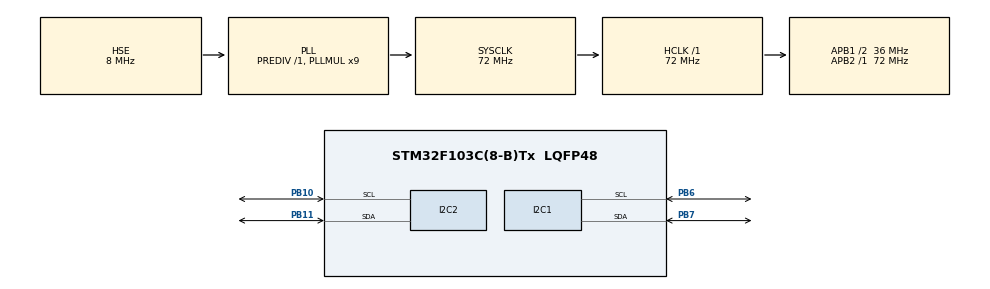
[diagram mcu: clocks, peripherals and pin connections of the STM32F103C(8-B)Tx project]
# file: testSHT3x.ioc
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Mcu.Family=STM32F1
Mcu.Name=STM32F103C(8-B)Tx
Mcu.Package=LQFP48
NVIC.PriorityGroup=NVIC_PRIORITYGROUP_4
PA13.Mode=Serial_Wire
PA13.Signal=SYS_JTMS-SWDIO
PA14.Mode=Serial_Wire
PA14.Signal=SYS_JTCK-SWCLK
PB10.Mode=I2C
PB10.Signal=I2C2_SCL
PB11.Mode=I2C
PB11.Signal=I2C2_SDA
PB6.Mode=I2C
PB6.Signal=I2C1_SCL
PB7.Mode=I2C
PB7.Signal=I2C1_SDA
PD0-OSC_IN.Mode=HSE-External-Oscillator
PD0-OSC_IN.Signal=RCC_OSC_IN
PD1-OSC_OUT.Mode=HSE-External-Oscillator
PD1-OSC_OUT.Signal=RCC_OSC_OUT
ProjectManager.HeapSize=0x200
ProjectManager.StackSize=0x400
ProjectManager.TargetToolchain=MDK-ARM V5.32
RCC.AHBFreq_Value=72000000
RCC.APB1CLKDivider=RCC_HCLK_DIV2
RCC.APB1Freq_Value=36000000
RCC.APB1TimFreq_Value=72000000
RCC.APB2Freq_Value=72000000
RCC.APB2TimFreq_Value=72000000
RCC.HCLKFreq_Value=72000000
RCC.PLLMUL=RCC_PLL_MUL9
RCC.PLLSourceVirtual=RCC_PLLSOURCE_HSE
RCC.SYSCLKFreq_VALUE=72000000
RCC.SYSCLKSource=RCC_SYSCLKSOURCE_PLLCLK
RCC.USBFreq_Value=72000000
board=custom

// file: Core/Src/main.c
/* USER CODE BEGIN Header */
/**
  ******************************************************************************
  * @file           : main.c
  * @brief          : Main program body
  ******************************************************************************
  * @attention
  *
  * Copyright (c) 2024 STMicroelectronics.
  * All rights reserved.
  *
  * This software is licensed under terms that can be found in the LICENSE file
  * in the root directory of this software component.
  * If no LICENSE file comes with this software, it is provided AS-IS.
  *
  ******************************************************************************
  */
/* USER CODE END Header */
#include "main.h"

/* USER CODE BEGIN PD */
uint8_t buffer_r[6] = {0,0,0,0,0,0};
uint8_t command_buffer[2] = {0x2C, 0x06};
float temp;
float temperature, humidity;
/* USER CODE END PD */

/* USER CODE BEGIN PM */
uint16_t uint8_to_uint16(uint8_t msb, uint8_t lsb)
{
	return (uint16_t)((uint16_t)msb << 8u) | lsb;
}
/* USER CODE END PM */

I2C_HandleTypeDef hi2c1;
I2C_HandleTypeDef hi2c2;

void SystemClock_Config(void);
static void MX_GPIO_Init(void);
static void MX_I2C2_Init(void);
static void MX_I2C1_Init(void);

int main(void)
{

  /* MCU Configuration--------------------------------------------------------*/

  /* Reset of all peripherals, Initializes the Flash interface and the Systick. */
  HAL_Init();

  /* Configure the system clock */
  SystemClock_Config();

  /* Initialize all configured peripherals */
  MX_GPIO_Init();
  MX_I2C2_Init();
  MX_I2C1_Init();
  /* USER CODE BEGIN 2 */
//	uint8_t i = 0, ret;
//	for(i=1; i<128; i++)
//    {
//        ret = HAL_I2C_IsDeviceReady(&hi2c2, 0x44 << 1u, 3, 5);
//        if (ret != HAL_OK) /* No ACK Received At That Address */
//        {
////            HAL_UART_Transmit(&huart1, Space, sizeof(Space), 10000);
//        }
//        else if(ret == HAL_OK)
//        {
//            sprintf(Buffer, "0x%X", i);
////            HAL_UART_Transmit(&huart1, Buffer, sizeof(Buffer), 10000);
//        }
//   }
  /* USER CODE END 2 */

  /* Infinite loop */
  while (1)
  {

    /* USER CODE BEGIN 3 */
		HAL_I2C_Master_Transmit(&hi2c2, 0x44 << 1u, command_buffer, sizeof(command_buffer), 200);
//		HAL_I2C_Master_Transmit(&hi2c1, 0x44 << 1u, command_buffer, sizeof(command_buffer), 200);
		//HAL_I2C_Master_Transmit(&hi2c1,0x44<<1u, buffer, sizeof(buffer),200);
		HAL_I2C_Master_Receive(&hi2c2 , 0x44<<1u, buffer_r, sizeof(buffer_r), 200);
		uint16_t temperature_raw = uint8_to_uint16(buffer_r[0], buffer_r[1]);
		uint16_t humidity_raw = uint8_to_uint16(buffer_r[3], buffer_r[4]);

		temperature = -45.0f + 175.0f * (float)temperature_raw / 65535.0f;
		humidity = 100.0f * (float)humidity_raw / 65535.0f;
  }
  /* USER CODE END 3 */
}

void SystemClock_Config(void)
{
  RCC_OscInitTypeDef RCC_OscInitStruct = {0};
  RCC_ClkInitTypeDef RCC_ClkInitStruct = {0};

  /** Initializes the RCC Oscillators according to the specified parameters
  * in the RCC_OscInitTypeDef structure.
  */
  RCC_OscInitStruct.OscillatorType = RCC_OSCILLATORTYPE_HSE;
  RCC_OscInitStruct.HSEState = RCC_HSE_ON;
  RCC_OscInitStruct.HSEPredivValue = RCC_HSE_PREDIV_DIV1;
  RCC_OscInitStruct.HSIState = RCC_HSI_ON;
  RCC_OscInitStruct.PLL.PLLState = RCC_PLL_ON;
  RCC_OscInitStruct.PLL.PLLSource = RCC_PLLSOURCE_HSE;
  RCC_OscInitStruct.PLL.PLLMUL = RCC_PLL_MUL9;
  if (HAL_RCC_OscConfig(&RCC_OscInitStruct) != HAL_OK)
  {
    Error_Handler();
  }

  /** Initializes the CPU, AHB and APB buses clocks
  */
  RCC_ClkInitStruct.ClockType = RCC_CLOCKTYPE_HCLK|RCC_CLOCKTYPE_SYSCLK
                              |RCC_CLOCKTYPE_PCLK1|RCC_CLOCKTYPE_PCLK2;
  RCC_ClkInitStruct.SYSCLKSource = RCC_SYSCLKSOURCE_PLLCLK;
  RCC_ClkInitStruct.AHBCLKDivider = RCC_SYSCLK_DIV1;
  RCC_ClkInitStruct.APB1CLKDivider = RCC_HCLK_DIV2;
  RCC_ClkInitStruct.APB2CLKDivider = RCC_HCLK_DIV1;

  if (HAL_RCC_ClockConfig(&RCC_ClkInitStruct, FLASH_LATENCY_2) != HAL_OK)
  {
    Error_Handler();
  }
}

static void MX_I2C1_Init(void)
{

  hi2c1.Instance = I2C1;
  hi2c1.Init.ClockSpeed = 100000;
  hi2c1.Init.DutyCycle = I2C_DUTYCYCLE_2;
  hi2c1.Init.OwnAddress1 = 0;
  hi2c1.Init.AddressingMode = I2C_ADDRESSINGMODE_7BIT;
  hi2c1.Init.DualAddressMode = I2C_DUALADDRESS_DISABLE;
  hi2c1.Init.OwnAddress2 = 0;
  hi2c1.Init.GeneralCallMode = I2C_GENERALCALL_DISABLE;
  hi2c1.Init.NoStretchMode = I2C_NOSTRETCH_DISABLE;
  if (HAL_I2C_Init(&hi2c1) != HAL_OK)
  {
    Error_Handler();
  }

}

static void MX_I2C2_Init(void)
{

  hi2c2.Instance = I2C2;
  hi2c2.Init.ClockSpeed = 100000;
  hi2c2.Init.DutyCycle = I2C_DUTYCYCLE_2;
  hi2c2.Init.OwnAddress1 = 0;
  hi2c2.Init.AddressingMode = I2C_ADDRESSINGMODE_7BIT;
  hi2c2.Init.DualAddressMode = I2C_DUALADDRESS_DISABLE;
  hi2c2.Init.OwnAddress2 = 0;
  hi2c2.Init.GeneralCallMode = I2C_GENERALCALL_DISABLE;
  hi2c2.Init.NoStretchMode = I2C_NOSTRETCH_DISABLE;
  if (HAL_I2C_Init(&hi2c2) != HAL_OK)
  {
    Error_Handler();
  }

}

static void MX_GPIO_Init(void)
{

  /* GPIO Ports Clock Enable */
  __HAL_RCC_GPIOD_CLK_ENABLE();
  __HAL_RCC_GPIOB_CLK_ENABLE();
  __HAL_RCC_GPIOA_CLK_ENABLE();

}

void Error_Handler(void)
{
  __disable_irq();
  while (1)
  {
  }
}
